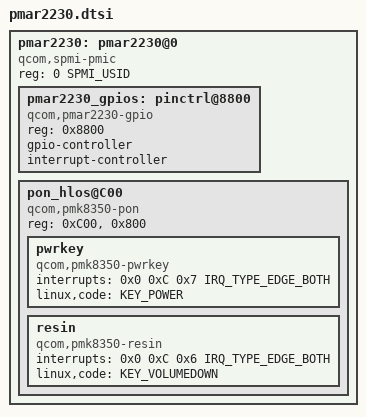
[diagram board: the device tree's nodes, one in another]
// SPDX-License-Identifier: BSD-3-Clause
/*
 * Copyright (c) Qualcomm Technologies, Inc. and/or its subsidiaries.
 */

#include <dt-bindings/input/input.h>
#include <dt-bindings/interrupt-controller/irq.h>
#include <dt-bindings/spmi/spmi.h>

pmar2230: pmar2230@0 {
		compatible = "qcom,spmi-pmic";
		reg = <0 SPMI_USID>;
		#address-cells = <1>;
		#size-cells = <0>;

		pmar2230_gpios: pinctrl@8800 {
			compatible = "qcom,pmar2230-gpio";
			reg = <0x8800>;
			gpio-controller;
			#gpio-cells = <2>;
			interrupt-controller;
			#interrupt-cells = <2>;
		};

		pon_hlos@C00 {
			compatible = "qcom,pmk8350-pon";
			reg = <0xC00>, <0x800>;
			reg-names = "hlos", "pbs";

			pwrkey {
				compatible = "qcom,pmk8350-pwrkey";
				interrupts = <0x0 0xC 0x7 IRQ_TYPE_EDGE_BOTH>;
				linux,code = <KEY_POWER>;
			};

			resin {
				compatible = "qcom,pmk8350-resin";
				interrupts = <0x0 0xC 0x6 IRQ_TYPE_EDGE_BOTH>;
				linux,code = <KEY_VOLUMEDOWN>;
			};
		};
};
